# STM32WL5x_CM0P register map
File version: 1.5
CPU: CM0 r0p1, little endian, MPU, no FPU, 4 interrupt priority bits
Registers are 32-bit, read-write, reset 0x0 unless marked. A register's access mark holds for its fields unless they carry their own. Offsets are from the block's base; [hi:lo] are bit positions; {n}, {i} and the like mark numbered series.

## USART1 — Universal synchronous asynchronous receiver transmitter
Base 0x40013800
Same registers: USART2 0x40004400
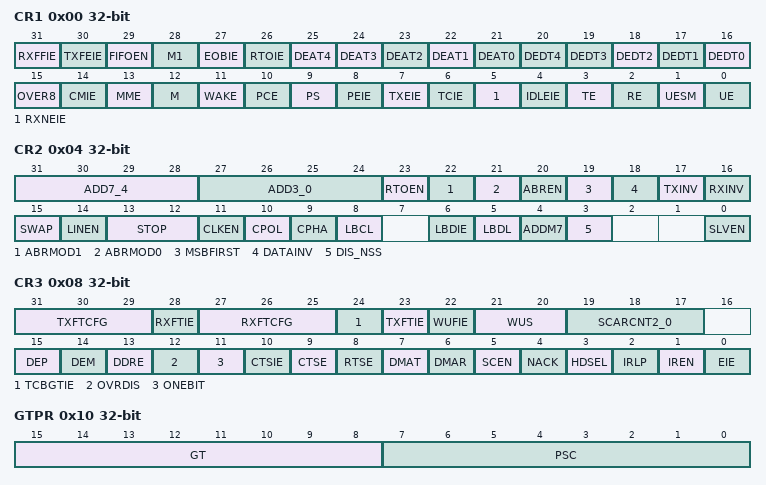
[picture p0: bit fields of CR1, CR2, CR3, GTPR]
0x00 CR1 — control register 1
  [31] RXFFIE — RXFIFO Full interrupt enable
  [30] TXFEIE — TXFIFO empty interrupt enable
  [29] FIFOEN — FIFO mode enable
  [28] M1 — Word length
  [27] EOBIE — End of Block interrupt enable
  [26] RTOIE — Receiver timeout interrupt enable
  [25] DEAT4 — Driver Enable assertion time
  [n+21] DEAT{n} (n=0..3)
  [20] DEDT4 — Driver Enable deassertion time
  [n+16] DEDT{n} (n=0..3)
  [15] OVER8 — Oversampling mode
  [14] CMIE — Character match interrupt enable
  [13] MME — Mute mode enable
  [12] M — Word length
  [11] WAKE — Receiver wakeup method
  [10] PCE — Parity control enable
  [9] PS — Parity selection
  [8] PEIE — PE interrupt enable
  [7] TXEIE — Transmit data register empty/TXFIFO not full interrupt enable
  [6] TCIE — Transmission complete interrupt enable
  [5] RXNEIE — Receive data register not empty/RXFIFO not empty interrupt enable
  [4] IDLEIE — IDLE interrupt enable
  [3] TE — Transmitter enable
  [2] RE — Receiver enable
  [1] UESM — USART enable in low-power mode
  [0] UE — USART enable
0x04 CR2 — control register 2
  [31:28] ADD7_4 — Address of the USART node
  [27:24] ADD3_0 — Address of the USART node
  [23] RTOEN — Receiver timeout enable
  [22] ABRMOD1 — Auto baud rate mode
  [21] ABRMOD0
  [20] ABREN — Auto baud rate enable
  [19] MSBFIRST — Most significant bit first
  [18] DATAINV — Binary data inversion
  [17] TXINV — TX pin active level inversion
  [16] RXINV — RX pin active level inversion
  [15] SWAP — Swap TX/RX pins
  [14] LINEN — LIN mode enable
  [13:12] STOP — stop bits
  [11] CLKEN — Clock enable
  [10] CPOL — Clock polarity
  [9] CPHA — Clock phase
  [8] LBCL — Last bit clock pulse
  [6] LBDIE — LIN break detection interrupt enable
  [5] LBDL — LIN break detection length
  [4] ADDM7 — 7-bit Address Detection/4-bit Address Detection
  [3] DIS_NSS
  [0] SLVEN — Synchronous Slave mode enable
0x08 CR3 — control register 3
  [31:29] TXFTCFG — TXFIFO threshold configuration
  [28] RXFTIE — RXFIFO threshold interrupt enable
  [27:25] RXFTCFG — Receive FIFO threshold configuration
  [24] TCBGTIE — Transmission Complete before guard time, interrupt enable
  [23] TXFTIE — TXFIFO threshold interrupt enable
  [22] WUFIE — Wakeup from low-power mode interrupt enable
  [21:20] WUS — Wakeup from low-power mode interrupt flag selection
  [19:17] SCARCNT2_0 — Smartcard auto-retry count
  [15] DEP — Driver enable polarity selection
  [14] DEM — Driver enable mode
  [13] DDRE — DMA Disable on Reception Error
  [12] OVRDIS — OVRDIS: Overrun Disable
  [11] ONEBIT — One sample bit method enable
  [10] CTSIE — CTS interrupt enable
  [9] CTSE — CTS enable
  [8] RTSE — RTS enable
  [7] DMAT — DMA enable transmitter
  [6] DMAR — DMA enable receiver
  [5] SCEN — Smartcard mode enable
  [4] NACK — Smartcard NACK enable
  [3] HDSEL — Half-duplex selection
  [2] IRLP — IrDA low-power
  [1] IREN — IrDA mode enable
  [0] EIE — Error interrupt enable
0x0C BRR — baud rate register
  [15:0] BRR
0x10 GTPR — guard time and prescaler register
  [15:8] GT — Guard time value
  [7:0] PSC — Prescaler value
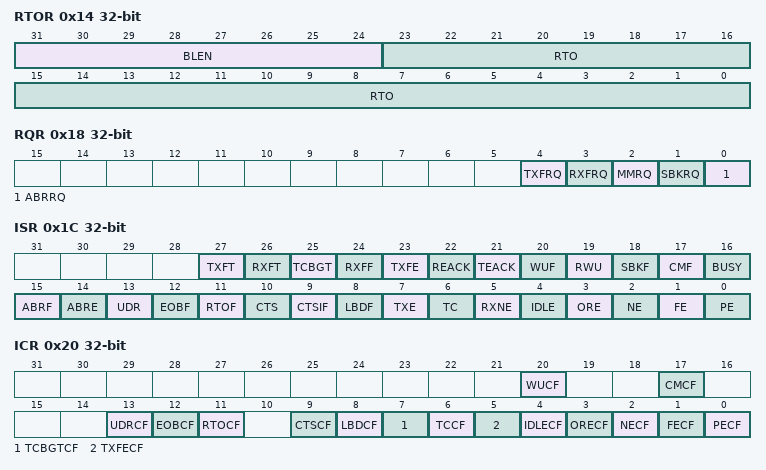
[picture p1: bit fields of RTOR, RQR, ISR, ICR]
0x14 RTOR — receiver timeout register
  [31:24] BLEN — Block Length
  [23:0] RTO — Receiver timeout value
0x18 RQR — request register
  [4] TXFRQ — Transmit data flush request
  [3] RXFRQ — Receive data flush request
  [2] MMRQ — Mute mode request
  [1] SBKRQ — Send break request
  [0] ABRRQ — Auto baud rate request
0x1C ISR ro — interrupt and status register
  [27] TXFT, [26] RXFT, [25] TCBGT, [24] RXFF, [23] TXFE, [22] REACK, [21] TEACK, [20] WUF, [19] RWU, [18] SBKF, [17] CMF, [16] BUSY, [15] ABRF, [14] ABRE, [13] UDR, [12] EOBF, [11] RTOF, [10] CTS, [9] CTSIF, [8] LBDF, [7] TXE, [6] TC, [5] RXNE, [4] IDLE, [3] ORE, [2] NE, [1] FE, [0] PE
0x20 ICR wo — interrupt flag clear register
  [20] WUCF — Wakeup from low-power mode clear flag
  [17] CMCF — Character match clear flag
  [13] UDRCF — SPI slave underrun clear flag
  [12] EOBCF — End of block clear flag
  [11] RTOCF — Receiver timeout clear flag
  [9] CTSCF — CTS clear flag
  [8] LBDCF — LIN break detection clear flag
  [7] TCBGTCF — Transmission complete before Guard time clear flag
  [6] TCCF — Transmission complete clear flag
  [5] TXFECF — TXFIFO empty clear flag
  [4] IDLECF — Idle line detected clear flag
  [3] ORECF — Overrun error clear flag
  [2] NECF — Noise detected clear flag
  [1] FECF — Framing error clear flag
  [0] PECF — Parity error clear flag
0x24 RDR ro — receive data register
  [8:0] RDR — Receive data value
0x28 TDR — transmit data register
  [8:0] TDR — Transmit data value
0x2C PRESC — prescaler register
  [3:0] PRESCALER — Clock prescaler
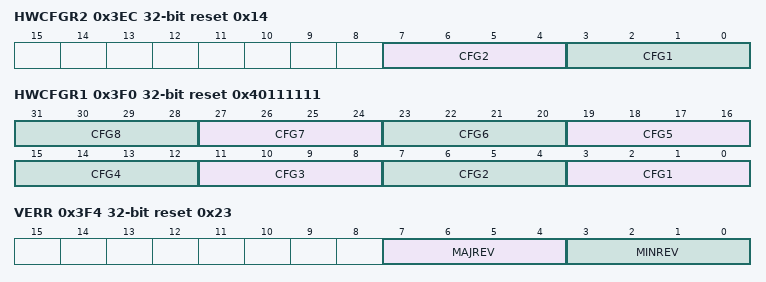
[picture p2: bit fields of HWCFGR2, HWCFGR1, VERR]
0x3EC HWCFGR2 ro reset 0x14 — Hardware Configuration register 2
  [7:4] CFG2 — USART hardware configuration 2
  [3:0] CFG1 — USART hardware configuration 1
0x3F0 HWCFGR1 ro reset 0x40111111 — Hardware Configuration register 1
  [4n-1:4n-4] CFG{n} (n=1..8) — USART hardware configuration {n}
0x3F4 VERR ro reset 0x23 — version register
  [7:4] MAJREV — Major revision
  [3:0] MINREV — Minor revision
0x3F8 IPIDR ro reset 0x130003 — Identification register
  [31:0] ID — Peripheral identifier
0x3FC SIDR ro reset 0xA3C5DD01 — Size Identification register
  [31:0] SID — Size identification
